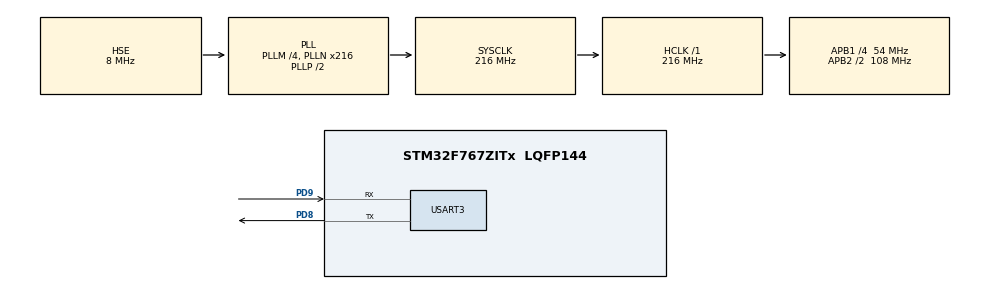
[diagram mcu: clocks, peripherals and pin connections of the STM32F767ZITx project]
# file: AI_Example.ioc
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CORTEX_M7.CPU_DCache=Enabled
CORTEX_M7.CPU_ICache=Enabled
Mcu.Family=STM32F7
Mcu.Name=STM32F767ZITx
Mcu.Package=LQFP144
NVIC.PriorityGroup=NVIC_PRIORITYGROUP_4
PD8.Mode=Asynchronous
PD8.Signal=USART3_TX
PD9.Mode=Asynchronous
PD9.Signal=USART3_RX
PH0/OSC_IN.Mode=HSE-External-Clock-Source
PH0/OSC_IN.Signal=RCC_OSC_IN
PH1/OSC_OUT.Mode=HSE-External-Clock-Source
PH1/OSC_OUT.Signal=RCC_OSC_OUT
ProjectManager.HeapSize=0x800
ProjectManager.StackSize=0x800
ProjectManager.TargetToolchain=STM32CubeIDE
RCC.AHBFreq_Value=216000000
RCC.APB1CLKDivider=RCC_HCLK_DIV4
RCC.APB1Freq_Value=54000000
RCC.APB1TimFreq_Value=108000000
RCC.APB2CLKDivider=RCC_HCLK_DIV2
RCC.APB2Freq_Value=108000000
RCC.APB2TimFreq_Value=216000000
RCC.CortexFreq_Value=216000000
RCC.HCLKFreq_Value=216000000
RCC.HSE_VALUE=8000000
RCC.HSI_VALUE=16000000
RCC.LSE_VALUE=32768
RCC.PLLM=4
RCC.PLLN=216
RCC.PLLSourceVirtual=RCC_PLLSOURCE_HSE
RCC.SYSCLKFreq_VALUE=216000000
RCC.SYSCLKSource=RCC_SYSCLKSOURCE_PLLCLK
RCC.USBFreq_Value=216000000
RCC.VCOOutputFreq_Value=432000000
STMicroelectronics.X-CUBE-AI.8.1.0.ActivationBufferSizeList=1940
STMicroelectronics.X-CUBE-AI.8.1.0.ActivationBuffers=pool0
STMicroelectronics.X-CUBE-AI.8.1.0.ActivationNames=pool0
STMicroelectronics.X-CUBE-AI.8.1.0.ActivationSizes=AI_SIN_MODEL_DATA_ACTIVATION_1_SIZE
STMicroelectronics.X-CUBE-AI.8.1.0.HeapSize=0x800
STMicroelectronics.X-CUBE-AI.8.1.0.InternalRamActivationBufferMaxSize=AI_SIN_MODEL_DATA_ACTIVATIONS_SIZE
STMicroelectronics.X-CUBE-AI.8.1.0.LatestDirectoryUsed-4eb05c29192c55d44c898c23c889ad3593036d6806840ceb9d9afffe9e8efe91=C\:\\Project\\ThermalCamera\\h5
STMicroelectronics.X-CUBE-AI.8.1.0.MaximumNumberOfInputLayer=1
STMicroelectronics.X-CUBE-AI.8.1.0.MaximumNumberOfOutputLayer=1
STMicroelectronics.X-CUBE-AI.8.1.0.MaximumSizeOfInputLayer=1
STMicroelectronics.X-CUBE-AI.8.1.0.MaximumSizeOfOutputLayer=1
STMicroelectronics.X-CUBE-AI.8.1.0.ModelActualCompression-4eb05c29192c55d44c898c23c889ad3593036d6806840ceb9d9afffe9e8efe91=0.0
STMicroelectronics.X-CUBE-AI.8.1.0.ModelCompression-4eb05c29192c55d44c898c23c889ad3593036d6806840ceb9d9afffe9e8efe91=None
STMicroelectronics.X-CUBE-AI.8.1.0.ModelFlashOccupation-4eb05c29192c55d44c898c23c889ad3593036d6806840ceb9d9afffe9e8efe91=14468
STMicroelectronics.X-CUBE-AI.8.1.0.ModelHashList=4eb05c29192c55d44c898c23c889ad3593036d6806840ceb9d9afffe9e8efe91
STMicroelectronics.X-CUBE-AI.8.1.0.ModelKind-4eb05c29192c55d44c898c23c889ad3593036d6806840ceb9d9afffe9e8efe91=TFLITE
STMicroelectronics.X-CUBE-AI.8.1.0.ModelMacc-4eb05c29192c55d44c898c23c889ad3593036d6806840ceb9d9afffe9e8efe91=353
STMicroelectronics.X-CUBE-AI.8.1.0.ModelName-4eb05c29192c55d44c898c23c889ad3593036d6806840ceb9d9afffe9e8efe91=sin_model
STMicroelectronics.X-CUBE-AI.8.1.0.ModelNameList=sin_model
STMicroelectronics.X-CUBE-AI.8.1.0.ModelRamOccupation-4eb05c29192c55d44c898c23c889ad3593036d6806840ceb9d9afffe9e8efe91=1940
STMicroelectronics.X-CUBE-AI.8.1.0.ModelStructureFile-4eb05c29192c55d44c898c23c889ad3593036d6806840ceb9d9afffe9e8efe91=C\:\\Project\\ThermalCamera\\h5\\sine_model.tflite
STMicroelectronics.X-CUBE-AI.8.1.0.ModelType-4eb05c29192c55d44c898c23c889ad3593036d6806840ceb9d9afffe9e8efe91=STM32Cube.AI runtime
STMicroelectronics.X-CUBE-AI.8.1.0.ReadyForCodeGeneration=true
STMicroelectronics.X-CUBE-AI.8.1.0.StackSize=0x800
STMicroelectronics.X-CUBE-AI.8.1.0.WorkingBufferStartAddrList=0xFFFFFFFF
STMicroelectronics.X-CUBE-AI.8.1.0.XAaCUBEAaAICcArtificialOoIntelligenceJjCore=true
STMicroelectronics.X-CUBE-AI.8.1.0.copyWeightToRam=false
STMicroelectronics.X-CUBE-AI.8.1.0.customLayerConfigEnabled=false
STMicroelectronics.X-CUBE-AI.8.1.0.noOnnxIoTranspose=false
STMicroelectronics.X-CUBE-AI.8.1.0.useInputAllocation=true
STMicroelectronics.X-CUBE-AI.8.1.0.useOutputAllocation=true
USART3.VirtualMode-Asynchronous=VM_ASYNC
VP_CRC_VS_CRC.Mode=CRC_Activate
VP_STMicroelectronics.X-CUBE-AI_VS_ArtificialOoIntelligenceJjXAaCUBEAaAI_8.1.0.Mode=ArtificialOoIntelligenceJjXAaCUBEAaAI
board=custom

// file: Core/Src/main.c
/* USER CODE BEGIN Header */
/**
  ******************************************************************************
  * @file           : main.c
  * @brief          : Main program body
  ******************************************************************************
  * @attention
  *
  * Copyright (c) 2024 STMicroelectronics.
  * All rights reserved.
  *
  * This software is licensed under terms that can be found in the LICENSE file
  * in the root directory of this software component.
  * If no LICENSE file comes with this software, it is provided AS-IS.
  *
  ******************************************************************************
  */
/* USER CODE END Header */
#include "main.h"
#include "crc.h"
#include "usart.h"
#include "gpio.h"

/* USER CODE BEGIN Includes */
#include "ai_datatypes_defines.h"
#include "sin_model.h"
#include "sin_model_data.h"
#include "ai_platform.h"
#include <stdint.h>
#include <stdlib.h>
#include <stdio.h>
#include <inttypes.h>
#include <string.h>

/* USER CODE END Includes */

/* USER CODE BEGIN PV */
#if !defined(AI_SIN_MODEL_INPUTS_IN_ACTIVATIONS)
AI_ALIGNED(4) ai_i8 data_in_1[AI_SIN_MODEL_IN_1_SIZE_BYTES];
ai_i8* data_ins[AI_SIN_MODEL_IN_NUM] = {
data_in_1
};
#else
ai_i8* data_ins[AI_SIN_MODEL_IN_NUM] = {
NULL
};
#endif

#if !defined(AI_SIN_MODEL_OUTPUTS_IN_ACTIVATIONS)
AI_ALIGNED(4) ai_i8 data_out_1[AI_SIN_MODEL_OUT_1_SIZE_BYTES];
ai_i8* data_outs[AI_SIN_MODEL_OUT_NUM] = {
data_out_1
};
#else
ai_i8* data_outs[AI_SIN_MODEL_OUT_NUM] = {
NULL
};
#endif

AI_ALIGNED(32)
static uint8_t pool0[AI_SIN_MODEL_DATA_ACTIVATION_1_SIZE];

ai_handle data_activations0[] = {pool0};

/* AI objects ----------------------------------------------------------------*/

static ai_handle sin_model = AI_HANDLE_NULL;

static ai_buffer* ai_input;
static ai_buffer* ai_output;

/* USER CODE END PV */

void SystemClock_Config(void);
/* USER CODE BEGIN PFP */
static void ai_log_err(const ai_error err, const char *fct)
{
  /* USER CODE BEGIN log */
  if (fct)
    printf("TEMPLATE - Error (%s) - type=0x%02x code=0x%02x\r\n", fct,
        err.type, err.code);
  else
    printf("TEMPLATE - Error - type=0x%02x code=0x%02x\r\n", err.type, err.code);

  do {} while (1);
  /* USER CODE END log */
}

static int ai_boostrap(ai_handle *act_addr)
{
  ai_error err;

  /* Create and initialize an instance of the model */
  err = ai_sin_model_create_and_init(&sin_model, act_addr, NULL);
  if (err.type != AI_ERROR_NONE) {
    ai_log_err(err, "ai_sin_model_create_and_init");
    return -1;
  }

  ai_input = ai_sin_model_inputs_get(sin_model, NULL);
  ai_output = ai_sin_model_outputs_get(sin_model, NULL);

#if defined(AI_SIN_MODEL_INPUTS_IN_ACTIVATIONS)
  /*  In the case where "--allocate-inputs" option is used, memory buffer can be
   *  used from the activations buffer. This is not mandatory.
   */
  for (int idx=0; idx < AI_SIN_MODEL_IN_NUM; idx++) {
	data_ins[idx] = ai_input[idx].data;
  }
#else
  for (int idx=0; idx < AI_SIN_MODEL_IN_NUM; idx++) {
	  ai_input[idx].data = data_ins[idx];
  }
#endif

#if defined(AI_SIN_MODEL_OUTPUTS_IN_ACTIVATIONS)
  /*  In the case where "--allocate-outputs" option is used, memory buffer can be
   *  used from the activations buffer. This is no mandatory.
   */
  for (int idx=0; idx < AI_SIN_MODEL_OUT_NUM; idx++) {
	data_outs[idx] = ai_output[idx].data;
  }
#else
  for (int idx=0; idx < AI_SIN_MODEL_OUT_NUM; idx++) {
	ai_output[idx].data = data_outs[idx];
  }
#endif

  return 0;
}

void MX_X_CUBE_AI_Init(void)
{
    /* USER CODE BEGIN 5 */
  printf("\r\nTEMPLATE - initialization\r\n");

  ai_boostrap(data_activations0);
    /* USER CODE END 5 */
}

/* USER CODE END PFP */

int main(void)
{
/* Enable the CPU Cache */

  /* Enable I-Cache---------------------------------------------------------*/
  SCB_EnableICache();

  /* Enable D-Cache---------------------------------------------------------*/
  SCB_EnableDCache();

  /* MCU Configuration--------------------------------------------------------*/

  /* Reset of all peripherals, Initializes the Flash interface and the Systick. */
  HAL_Init();

  /* Configure the system clock */
  SystemClock_Config();

  /* Initialize all configured peripherals */
  MX_GPIO_Init();
  MX_CRC_Init();
  MX_USART3_UART_Init();
  /* USER CODE BEGIN 2 */

  MX_X_CUBE_AI_Init();
  /* USER CODE END 2 */

  /* Infinite loop */
  /* USER CODE BEGIN WHILE */
  float input_value = 1.0f; // 모델 입력값으로 사용할 값
  while (1)
  {
	  ai_i32 batch;
	  *((float*)data_ins[0]) = input_value; // 첫 번째 입력 버퍼에 값을 설정

	  if (ai_sin_model_run(sin_model, ai_input, ai_output) != 1) {
	      // 모델 실행에 실패한 경우 오류 처리
	      ai_log_err(ai_sin_model_get_error(sin_model), "ai_sin_model_run");
	      return -1;
	  }
	  float output_value = *((float*)data_outs[0]);
	  input_value += 1.0;
    /* USER CODE END WHILE */

  }
}

void SystemClock_Config(void)
{
  RCC_OscInitTypeDef RCC_OscInitStruct = {0};
  RCC_ClkInitTypeDef RCC_ClkInitStruct = {0};

  /** Configure the main internal regulator output voltage
  */
  __HAL_RCC_PWR_CLK_ENABLE();
  __HAL_PWR_VOLTAGESCALING_CONFIG(PWR_REGULATOR_VOLTAGE_SCALE1);

  /** Initializes the RCC Oscillators according to the specified parameters
  * in the RCC_OscInitTypeDef structure.
  */
  RCC_OscInitStruct.OscillatorType = RCC_OSCILLATORTYPE_HSE;
  RCC_OscInitStruct.HSEState = RCC_HSE_BYPASS;
  RCC_OscInitStruct.PLL.PLLState = RCC_PLL_ON;
  RCC_OscInitStruct.PLL.PLLSource = RCC_PLLSOURCE_HSE;
  RCC_OscInitStruct.PLL.PLLM = 4;
  RCC_OscInitStruct.PLL.PLLN = 216;
  RCC_OscInitStruct.PLL.PLLP = RCC_PLLP_DIV2;
  RCC_OscInitStruct.PLL.PLLQ = 2;
  RCC_OscInitStruct.PLL.PLLR = 2;
  if (HAL_RCC_OscConfig(&RCC_OscInitStruct) != HAL_OK)
  {
    Error_Handler();
  }

  /** Activate the Over-Drive mode
  */
  if (HAL_PWREx_EnableOverDrive() != HAL_OK)
  {
    Error_Handler();
  }

  /** Initializes the CPU, AHB and APB buses clocks
  */
  RCC_ClkInitStruct.ClockType = RCC_CLOCKTYPE_HCLK|RCC_CLOCKTYPE_SYSCLK
                              |RCC_CLOCKTYPE_PCLK1|RCC_CLOCKTYPE_PCLK2;
  RCC_ClkInitStruct.SYSCLKSource = RCC_SYSCLKSOURCE_PLLCLK;
  RCC_ClkInitStruct.AHBCLKDivider = RCC_SYSCLK_DIV1;
  RCC_ClkInitStruct.APB1CLKDivider = RCC_HCLK_DIV4;
  RCC_ClkInitStruct.APB2CLKDivider = RCC_HCLK_DIV2;

  if (HAL_RCC_ClockConfig(&RCC_ClkInitStruct, FLASH_LATENCY_7) != HAL_OK)
  {
    Error_Handler();
  }
}

void Error_Handler(void)
{
  __disable_irq();
  while (1)
  {
  }
}
